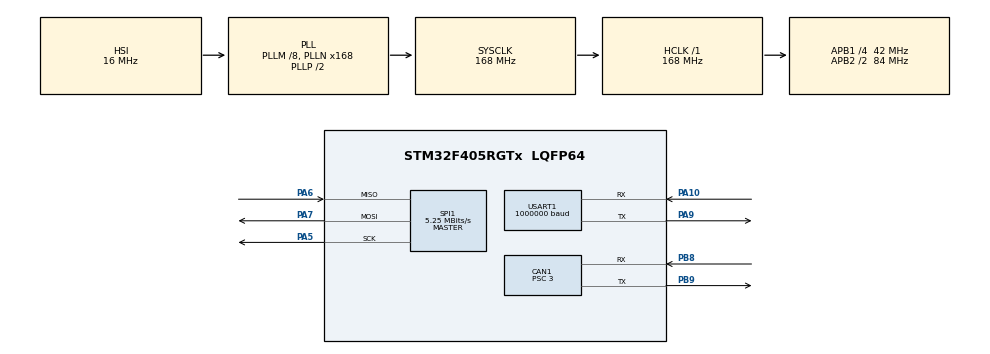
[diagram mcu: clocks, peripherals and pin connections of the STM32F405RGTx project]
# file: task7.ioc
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CAN1.BS1=CAN_BS1_10TQ
CAN1.BS2=CAN_BS2_3TQ
CAN1.CalculateBaudRate=1000000
CAN1.CalculateTimeBit=1000
CAN1.CalculateTimeQuantum=71.42857142857143
CAN1.NART=ENABLE
CAN1.Prescaler=3
Mcu.Family=STM32F4
Mcu.Name=STM32F405RGTx
Mcu.Package=LQFP64
NVIC.CAN1_RX0_IRQn=true\:0\:0\:false\:false\:true\:true\:true\:true
NVIC.CAN1_TX_IRQn=true\:0\:0\:false\:false\:true\:true\:true\:true
NVIC.PriorityGroup=NVIC_PRIORITYGROUP_4
NVIC.TIM7_IRQn=true\:0\:0\:false\:false\:true\:true\:true\:true
NVIC.USART1_IRQn=true\:0\:0\:false\:false\:true\:true\:true\:true
PA10.Mode=Asynchronous
PA10.Signal=USART1_RX
PA13.Mode=Serial_Wire
PA13.Signal=SYS_JTMS-SWDIO
PA14.Mode=Serial_Wire
PA14.Signal=SYS_JTCK-SWCLK
PA5.Mode=Full_Duplex_Master
PA5.Signal=SPI1_SCK
PA6.Mode=Full_Duplex_Master
PA6.Signal=SPI1_MISO
PA7.Mode=Full_Duplex_Master
PA7.Signal=SPI1_MOSI
PA9.Mode=Asynchronous
PA9.Signal=USART1_TX
PB8.Mode=CAN_Activate
PB8.Signal=CAN1_RX
PB9.Mode=CAN_Activate
PB9.Signal=CAN1_TX
PH0-OSC_IN.Mode=HSE-External-Oscillator
PH0-OSC_IN.Signal=RCC_OSC_IN
PH1-OSC_OUT.Mode=HSE-External-Oscillator
PH1-OSC_OUT.Signal=RCC_OSC_OUT
ProjectManager.HeapSize=0x200
ProjectManager.StackSize=0x400
ProjectManager.TargetToolchain=MDK-ARM V5.32
RCC.48MHZClocksFreq_Value=84000000
RCC.AHBFreq_Value=168000000
RCC.APB1CLKDivider=RCC_HCLK_DIV4
RCC.APB1Freq_Value=42000000
RCC.APB1TimFreq_Value=84000000
RCC.APB2CLKDivider=RCC_HCLK_DIV2
RCC.APB2Freq_Value=84000000
RCC.APB2TimFreq_Value=168000000
RCC.CortexFreq_Value=168000000
RCC.HCLKFreq_Value=168000000
RCC.HSE_VALUE=25000000
RCC.HSI_VALUE=16000000
RCC.LSE_VALUE=32768
RCC.PLLM=8
RCC.PLLN=168
RCC.SYSCLKFreq_VALUE=168000000
RCC.SYSCLKSource=RCC_SYSCLKSOURCE_PLLCLK
RCC.VCOOutputFreq_Value=336000000
SPI1.BaudRatePrescaler=SPI_BAUDRATEPRESCALER_16
SPI1.CLKPhase=SPI_PHASE_2EDGE
SPI1.CalculateBaudRate=5.25 MBits/s
SPI1.DataSize=SPI_DATASIZE_16BIT
SPI1.Direction=SPI_DIRECTION_2LINES
SPI1.Mode=SPI_MODE_MASTER
SPI1.VirtualType=VM_MASTER
TIM7.AutoReloadPreload=TIM_AUTORELOAD_PRELOAD_ENABLE
TIM7.Period=999
TIM7.Prescaler=83
USART1.BaudRate=1000000
USART1.VirtualMode=VM_ASYNC
VP_TIM7_VS_ClockSourceINT.Mode=Enable_Timer
board=custom

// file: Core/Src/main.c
/* USER CODE BEGIN Header */
/**
  ******************************************************************************
  * @file           : main.c
  * @brief          : Main program body
  ******************************************************************************
  * @attention
  *
  * Copyright (c) 2026 STMicroelectronics.
  * All rights reserved.
  *
  * This software is licensed under terms that can be found in the LICENSE file
  * in the root directory of this software component.
  * If no LICENSE file comes with this software, it is provided AS-IS.
  *
  ******************************************************************************
  */
/* USER CODE END Header */
#include "main.h"

/* USER CODE BEGIN Includes */
#include "bsp_can.h"
#include "Bsp_Control_Timer.h"
#include "dji_motor.h"
#include "motor_param.h"
#include "motor_control.h"
#include "user_main.h"

/* USER CODE END Includes */

CAN_HandleTypeDef hcan1;

SPI_HandleTypeDef hspi1;

TIM_HandleTypeDef htim7;

UART_HandleTypeDef huart1;

void SystemClock_Config(void);
static void MX_GPIO_Init(void);
static void MX_CAN1_Init(void);
static void MX_SPI1_Init(void);
static void MX_TIM7_Init(void);
static void MX_USART1_UART_Init(void);

int main(void)
{

  /* MCU Configuration--------------------------------------------------------*/

  /* Reset of all peripherals, Initializes the Flash interface and the Systick. */
  HAL_Init();

  /* Configure the system clock */
  SystemClock_Config();

  /* Initialize all configured peripherals */
  MX_GPIO_Init();
  MX_CAN1_Init();
  MX_SPI1_Init();
  MX_TIM7_Init();
  MX_USART1_UART_Init();
  /* USER CODE BEGIN 2 */
  user_main_init();
  /* USER CODE END 2 */

  /* Infinite loop */
  /* USER CODE BEGIN WHILE */
  while (1)
  {
    user_main_loop();
    /* USER CODE END WHILE */

    /* USER CODE BEGIN 3 */
    /* CubeMX template omits the while-loop closing brace in this project. */
  }

  /* USER CODE END 3 */
}

void SystemClock_Config(void)
{
  RCC_OscInitTypeDef RCC_OscInitStruct = {0};
  RCC_ClkInitTypeDef RCC_ClkInitStruct = {0};

  /** Configure the main internal regulator output voltage
  */
  __HAL_RCC_PWR_CLK_ENABLE();
  __HAL_PWR_VOLTAGESCALING_CONFIG(PWR_REGULATOR_VOLTAGE_SCALE1);

  /** Initializes the RCC Oscillators according to the specified parameters
  * in the RCC_OscInitTypeDef structure.
  */
  RCC_OscInitStruct.OscillatorType = RCC_OSCILLATORTYPE_HSI;
  RCC_OscInitStruct.HSIState = RCC_HSI_ON;
  RCC_OscInitStruct.HSICalibrationValue = RCC_HSICALIBRATION_DEFAULT;
  RCC_OscInitStruct.PLL.PLLState = RCC_PLL_ON;
  RCC_OscInitStruct.PLL.PLLSource = RCC_PLLSOURCE_HSI;
  RCC_OscInitStruct.PLL.PLLM = 8;
  RCC_OscInitStruct.PLL.PLLN = 168;
  RCC_OscInitStruct.PLL.PLLP = RCC_PLLP_DIV2;
  RCC_OscInitStruct.PLL.PLLQ = 4;
  if (HAL_RCC_OscConfig(&RCC_OscInitStruct) != HAL_OK)
  {
    Error_Handler();
  }

  /** Initializes the CPU, AHB and APB buses clocks
  */
  RCC_ClkInitStruct.ClockType = RCC_CLOCKTYPE_HCLK|RCC_CLOCKTYPE_SYSCLK
                              |RCC_CLOCKTYPE_PCLK1|RCC_CLOCKTYPE_PCLK2;
  RCC_ClkInitStruct.SYSCLKSource = RCC_SYSCLKSOURCE_PLLCLK;
  RCC_ClkInitStruct.AHBCLKDivider = RCC_SYSCLK_DIV1;
  RCC_ClkInitStruct.APB1CLKDivider = RCC_HCLK_DIV4;
  RCC_ClkInitStruct.APB2CLKDivider = RCC_HCLK_DIV2;

  if (HAL_RCC_ClockConfig(&RCC_ClkInitStruct, FLASH_LATENCY_5) != HAL_OK)
  {
    Error_Handler();
  }
}

static void MX_CAN1_Init(void)
{

  hcan1.Instance = CAN1;
  hcan1.Init.Prescaler = 3;
  hcan1.Init.Mode = CAN_MODE_NORMAL;
  hcan1.Init.SyncJumpWidth = CAN_SJW_1TQ;
  hcan1.Init.TimeSeg1 = CAN_BS1_10TQ;
  hcan1.Init.TimeSeg2 = CAN_BS2_3TQ;
  hcan1.Init.TimeTriggeredMode = DISABLE;
  hcan1.Init.AutoBusOff = DISABLE;
  hcan1.Init.AutoWakeUp = DISABLE;
  hcan1.Init.AutoRetransmission = ENABLE;
  hcan1.Init.ReceiveFifoLocked = DISABLE;
  hcan1.Init.TransmitFifoPriority = DISABLE;
  if (HAL_CAN_Init(&hcan1) != HAL_OK)
  {
    Error_Handler();
  }

}

static void MX_SPI1_Init(void)
{

  /* SPI1 parameter configuration*/
  hspi1.Instance = SPI1;
  hspi1.Init.Mode = SPI_MODE_MASTER;
  hspi1.Init.Direction = SPI_DIRECTION_2LINES;
  hspi1.Init.DataSize = SPI_DATASIZE_16BIT;
  hspi1.Init.CLKPolarity = SPI_POLARITY_LOW;
  hspi1.Init.CLKPhase = SPI_PHASE_2EDGE;
  hspi1.Init.NSS = SPI_NSS_SOFT;
  hspi1.Init.BaudRatePrescaler = SPI_BAUDRATEPRESCALER_16;
  hspi1.Init.FirstBit = SPI_FIRSTBIT_MSB;
  hspi1.Init.TIMode = SPI_TIMODE_DISABLE;
  hspi1.Init.CRCCalculation = SPI_CRCCALCULATION_DISABLE;
  hspi1.Init.CRCPolynomial = 10;
  if (HAL_SPI_Init(&hspi1) != HAL_OK)
  {
    Error_Handler();
  }

}

static void MX_TIM7_Init(void)
{

  TIM_MasterConfigTypeDef sMasterConfig = {0};

  htim7.Instance = TIM7;
  htim7.Init.Prescaler = 83;
  htim7.Init.CounterMode = TIM_COUNTERMODE_UP;
  htim7.Init.Period = 999;
  htim7.Init.AutoReloadPreload = TIM_AUTORELOAD_PRELOAD_ENABLE;
  if (HAL_TIM_Base_Init(&htim7) != HAL_OK)
  {
    Error_Handler();
  }
  sMasterConfig.MasterOutputTrigger = TIM_TRGO_RESET;
  sMasterConfig.MasterSlaveMode = TIM_MASTERSLAVEMODE_DISABLE;
  if (HAL_TIMEx_MasterConfigSynchronization(&htim7, &sMasterConfig) != HAL_OK)
  {
    Error_Handler();
  }

}

static void MX_USART1_UART_Init(void)
{

  huart1.Instance = USART1;
  huart1.Init.BaudRate = 1000000;
  huart1.Init.WordLength = UART_WORDLENGTH_8B;
  huart1.Init.StopBits = UART_STOPBITS_1;
  huart1.Init.Parity = UART_PARITY_NONE;
  huart1.Init.Mode = UART_MODE_TX_RX;
  huart1.Init.HwFlowCtl = UART_HWCONTROL_NONE;
  huart1.Init.OverSampling = UART_OVERSAMPLING_16;
  if (HAL_UART_Init(&huart1) != HAL_OK)
  {
    Error_Handler();
  }

}

static void MX_GPIO_Init(void)
{

  /* GPIO Ports Clock Enable */
  __HAL_RCC_GPIOH_CLK_ENABLE();
  __HAL_RCC_GPIOA_CLK_ENABLE();
  __HAL_RCC_GPIOB_CLK_ENABLE();

}

void Error_Handler(void)
{
  __disable_irq();
  while (1)
  {
  }
}
